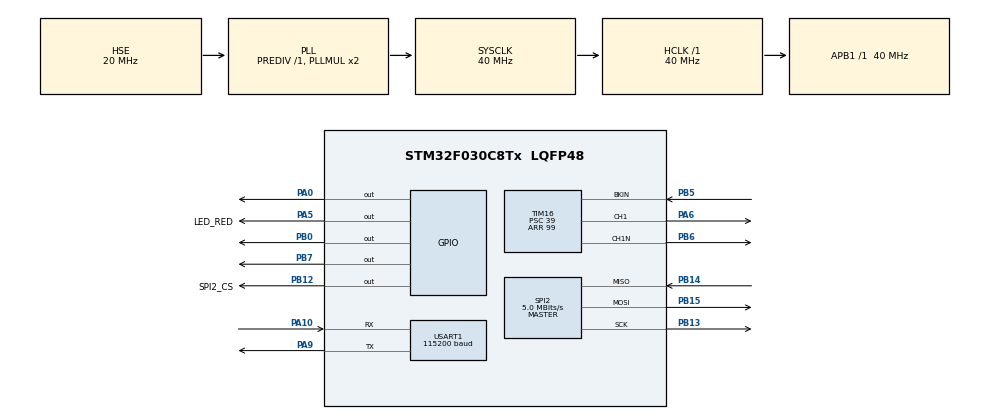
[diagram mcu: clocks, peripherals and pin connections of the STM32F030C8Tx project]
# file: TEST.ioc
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Mcu.Family=STM32F0
Mcu.Name=STM32F030C8Tx
Mcu.Package=LQFP48
NVIC.USART1_IRQn=true\:3\:0\:true\:false\:true\:true\:true\:true
PA0.GPIO_ModeDefaultOutputPP=GPIO_MODE_OUTPUT_PP
PA0.GPIO_PuPd=GPIO_NOPULL
PA0.GPIO_Speed=GPIO_SPEED_FREQ_LOW
PA0.PinState=GPIO_PIN_SET
PA0.Signal=GPIO_Output
PA10.GPIO_PuPd=GPIO_PULLUP
PA10.Mode=Asynchronous
PA10.Signal=USART1_RX
PA5.GPIO_Label=LED_RED
PA5.GPIO_ModeDefaultOutputPP=GPIO_MODE_OUTPUT_PP
PA5.GPIO_PuPd=GPIO_NOPULL
PA5.PinState=GPIO_PIN_SET
PA5.Signal=GPIO_Output
PA6.GPIO_Speed=GPIO_SPEED_FREQ_LOW
PA6.Signal=S_TIM16_CH1
PA9.GPIO_PuPd=GPIO_PULLUP
PA9.Mode=Asynchronous
PA9.Signal=USART1_TX
PB0.GPIO_Speed=GPIO_SPEED_FREQ_LOW
PB0.PinState=GPIO_PIN_SET
PB0.Signal=GPIO_Output
PB12.GPIO_Label=SPI2_CS
PB12.GPIO_PuPd=GPIO_PULLUP
PB12.GPIO_Speed=GPIO_SPEED_FREQ_HIGH
PB12.PinState=GPIO_PIN_SET
PB12.Signal=GPIO_Output
PB13.Mode=Full_Duplex_Master
PB13.Signal=SPI2_SCK
PB14.Mode=Full_Duplex_Master
PB14.Signal=SPI2_MISO
PB15.Mode=Full_Duplex_Master
PB15.Signal=SPI2_MOSI
PB5.Mode=Activate-Break-Input
PB5.Signal=TIM16_BKIN
PB6.GPIO_FM6=__NULL
PB6.GPIO_Speed=GPIO_SPEED_FREQ_LOW
PB6.Mode=Output Compare1 CH1 CH1N
PB6.Signal=TIM16_CH1N
PB7.GPIO_ModeDefaultOutputPP=GPIO_MODE_OUTPUT_PP
PB7.GPIO_Speed=GPIO_SPEED_FREQ_LOW
PB7.PinState=GPIO_PIN_SET
PB7.Signal=GPIO_Output
PF0-OSC_IN.Mode=HSE-External-Oscillator
PF0-OSC_IN.Signal=RCC_OSC_IN
PF1-OSC_OUT.Mode=HSE-External-Oscillator
PF1-OSC_OUT.Signal=RCC_OSC_OUT
ProjectManager.HeapSize=0x200
ProjectManager.StackSize=0x400
ProjectManager.TargetToolchain=MDK-ARM V5.32
RCC.AHBFreq_Value=40000000
RCC.APB1Freq_Value=40000000
RCC.APB1TimFreq_Value=40000000
RCC.HCLKFreq_Value=40000000
RCC.HSE_VALUE=20000000
RCC.PLLSourceVirtual=RCC_PLLSOURCE_HSE
RCC.SYSCLKFreq_VALUE=40000000
RCC.SYSCLKSource=RCC_SYSCLKSOURCE_PLLCLK
SH.S_TIM16_CH1.0=TIM16_CH1,Output Compare1 CH1 CH1N
SPI2.BaudRatePrescaler=SPI_BAUDRATEPRESCALER_8
SPI2.CLKPhase=SPI_PHASE_2EDGE
SPI2.CalculateBaudRate=5.0 MBits/s
SPI2.DataSize=SPI_DATASIZE_8BIT
SPI2.Direction=SPI_DIRECTION_2LINES
SPI2.Mode=SPI_MODE_MASTER
SPI2.VirtualType=VM_MASTER
TIM16.BreakPolarity=TIM_BREAKPOLARITY_HIGH
TIM16.BreakState=TIM_BREAK_ENABLE
TIM16.Channel=TIM_CHANNEL_1
TIM16.DeadTime=80
TIM16.OC1Preload=ENABLE
TIM16.OCMode_1=TIM_OCMODE_TOGGLE
TIM16.OCNIdleState_1=TIM_OCNIDLESTATE_RESET
TIM16.OCNPolarity_1=TIM_OCNPOLARITY_HIGH
TIM16.OffStateIDLEMode=TIM_OSSI_DISABLE
TIM16.OffStateRunMode=TIM_OSSR_DISABLE
TIM16.Period=99
TIM16.Prescaler=39
TIM16.Pulse=20
USART1.BaudRate=115200
USART1.OverSampling=UART_OVERSAMPLING_8
USART1.VirtualMode-Asynchronous=VM_ASYNC
VP_TIM16_VS_ClockSourceINT.Mode=Enable_Timer
board=custom

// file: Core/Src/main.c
/* USER CODE BEGIN Header */
/**
  ******************************************************************************
  * @file           : main.c
  * @brief          : Main program body
  ******************************************************************************
  * @attention
  *
  * Copyright (c) 2023 STMicroelectronics.
  * All rights reserved.
  *
  * This software is licensed under terms that can be found in the LICENSE file
  * in the root directory of this software component.
  * If no LICENSE file comes with this software, it is provided AS-IS.
  *
  ******************************************************************************
  */
/* USER CODE END Header */
#include "main.h"
#include "spi.h"
#include "tim.h"
#include "usart.h"
#include "gpio.h"

/* USER CODE BEGIN Includes */
#include "stdio.h"
/* USER CODE END Includes */

/* USER CODE BEGIN PTD */
//uint8_t * RxBuffer;
uint8_t RxBuffer[RXBUFFERSIZE];   //接收数据
uint8_t aRxBuffer;			    //接收中断缓冲
uint8_t Uart1_Rx_Cnt = 0;		//接收缓冲计数
uint8_t USART_RX_STA = 0;     //串口接收状态
/* USER CODE END PTD */

void SystemClock_Config(void);

int main(void)
{

  /* MCU Configuration--------------------------------------------------------*/

  /* Reset of all peripherals, Initializes the Flash interface and the Systick. */
  HAL_Init();

  /* Configure the system clock */
  SystemClock_Config();

  /* Initialize all configured peripherals */
  MX_GPIO_Init();
  MX_SPI2_Init();
	delay_init(40);
  MX_TIM16_Init();
  MX_USART1_UART_Init();
  /* USER CODE BEGIN 2 */
	#ifndef Custom_Uart1_EN
  HAL_UART_Receive_IT(&huart1, (uint8_t *)&aRxBuffer, 1);
  #endif
  IIC_Init();
	delay_us(100);
	INA226_Init();
	HAL_GPIO_WritePin(LED_RED_GPIO_Port,LED_RED_Pin,GPIO_PIN_RESET);
  /* USER CODE END 2 */

  /* Infinite loop */
  /* USER CODE BEGIN WHILE */
	//DEBUG("测试板程序成功启动");
  while (1)
  {
	//  delay_us(100);
	//	HAL_TIM_PWM_Start(&htim16,TIM_CHANNEL_1);
	 // HAL_TIMEx_PWMN_Start(&htim16,TIM_CHANNEL_1);
	//	printf("cyskkk");
	//	delay_ms(500);
	  LOW_COMPUTER_CTROL();
	//	printf("Bus_V  =%f mV          ",INA226_Read2Byte(Bus_V_Reg)*1.25);

    /* USER CODE END WHILE */

  }
}

void SystemClock_Config(void)
{
  RCC_OscInitTypeDef RCC_OscInitStruct = {0};
  RCC_ClkInitTypeDef RCC_ClkInitStruct = {0};
  RCC_PeriphCLKInitTypeDef PeriphClkInit = {0};

  /** Initializes the RCC Oscillators according to the specified parameters
  * in the RCC_OscInitTypeDef structure.
  */
  RCC_OscInitStruct.OscillatorType = RCC_OSCILLATORTYPE_HSE;
  RCC_OscInitStruct.HSEState = RCC_HSE_ON;
  RCC_OscInitStruct.PLL.PLLState = RCC_PLL_ON;
  RCC_OscInitStruct.PLL.PLLSource = RCC_PLLSOURCE_HSE;
  RCC_OscInitStruct.PLL.PLLMUL = RCC_PLL_MUL2;
  RCC_OscInitStruct.PLL.PREDIV = RCC_PREDIV_DIV1;
  if (HAL_RCC_OscConfig(&RCC_OscInitStruct) != HAL_OK)
  {
    Error_Handler();
  }

  /** Initializes the CPU, AHB and APB buses clocks
  */
  RCC_ClkInitStruct.ClockType = RCC_CLOCKTYPE_HCLK|RCC_CLOCKTYPE_SYSCLK
                              |RCC_CLOCKTYPE_PCLK1;
  RCC_ClkInitStruct.SYSCLKSource = RCC_SYSCLKSOURCE_PLLCLK;
  RCC_ClkInitStruct.AHBCLKDivider = RCC_SYSCLK_DIV1;
  RCC_ClkInitStruct.APB1CLKDivider = RCC_HCLK_DIV1;

  if (HAL_RCC_ClockConfig(&RCC_ClkInitStruct, FLASH_LATENCY_1) != HAL_OK)
  {
    Error_Handler();
  }
  PeriphClkInit.PeriphClockSelection = RCC_PERIPHCLK_USART1;
  PeriphClkInit.Usart1ClockSelection = RCC_USART1CLKSOURCE_PCLK1;
  if (HAL_RCCEx_PeriphCLKConfig(&PeriphClkInit) != HAL_OK)
  {
    Error_Handler();
  }
}

void Error_Handler(void)
{
  __disable_irq();
  while (1)
  {
  }
}
